# GD32A72_A74x register map
File version: 1.0
CPU: CM7 r2p1, little endian, MPU, FPU, DSP, 4 interrupt priority bits
Registers are 32-bit, read-write, reset 0x0 unless marked. A register's access mark holds for its fields unless they carry their own. Offsets are from the block's base; [hi:lo] are bit positions; {n}, {i} and the like mark numbered series; 'fields as' and 'values as' point back to an identical list.

## TCM
Base 0x49004000
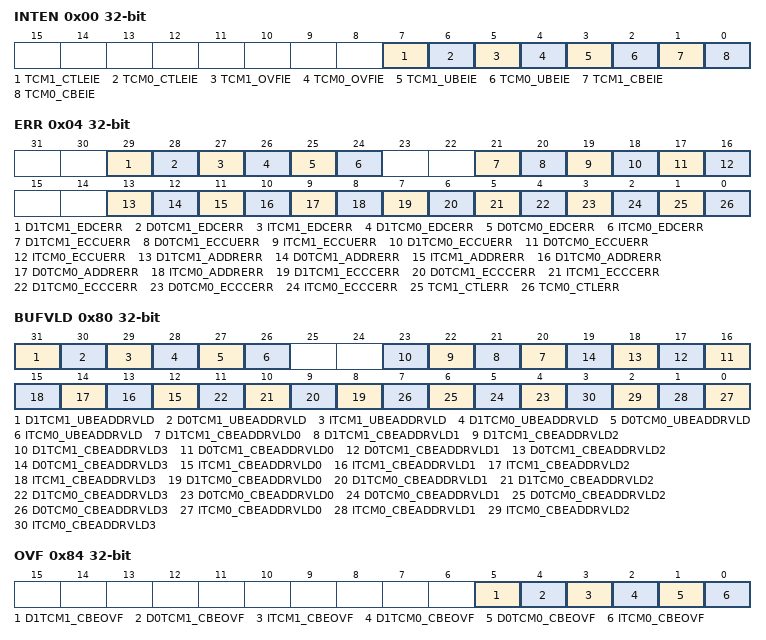
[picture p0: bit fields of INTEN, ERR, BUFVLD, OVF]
0x00 INTEN — TCM interrupt enable register
  [7] TCM1_CTLEIE — TCM of CM7_1 controller redundancy check error interrupt enable
  [6] TCM0_CTLEIE — TCM of CM7_0 controller redundancy check error interrupt enable
  [5] TCM1_OVFIE — TCM of M7_1 address buffer overflow interrupt enable
  [4] TCM0_OVFIE — TCM of M7_0 address buffer overflow interrupt enable
  [3] TCM1_UBEIE — TCM of M7_1 uncorrectable bit error interrupt enable
  [2] TCM0_UBEIE — TCM of M7_0 uncorrectable bit error interrupt enable
  [1] TCM1_CBEIE — TCM of M7_1 correctable bit error interrupt enable
  [0] TCM0_CBEIE — TCM of M7_0 correctable bit error interrupt enable
0x04 ERR — TCM error status register
  [29] D1TCM1_EDCERR — D1TCM of M7_1 EDC after ECC checker error flag
  [28] D0TCM1_EDCERR — D0TCM of M7_1 EDC after ECC checker error flag
  [27] ITCM1_EDCERR — ITCM of M7_1 EDC after ECC checker error flag
  [26] D1TCM0_EDCERR — D1TCM of M7_0 EDC after ECC checker error flag
  [25] D0TCM0_EDCERR — D0TCM of M7_0 EDC after ECC checker error flag
  [24] ITCM0_EDCERR — ITCM of M7_0 EDC after ECC checker error flag
  [21] D1TCM1_ECCUERR — D1TCM of M7_1 ECC double bit uncorrectable error flag
  [20] D0TCM1_ECCUERR — D0TCM of M7_1 ECC double bit uncorrectable error flag
  [19] ITCM1_ECCUERR — ITCM of M7_1 ECC double bit uncorrectable error flag
  [18] D1TCM0_ECCUERR — D1TCM of M7_0 ECC double bit uncorrectable error flag
  [17] D0TCM0_ECCUERR — D0TCM of M7_0 ECC double bit uncorrectable error flag
  [16] ITCM0_ECCUERR — ITCM of M7_0 ECC double bit uncorrectable error flag
  [13] D1TCM1_ADDRERR — D1TCM of M7_1 single bit address error flag
  [12] D0TCM1_ADDRERR — D0TCM of M7_1 single bit address error flag
  [11] ITCM1_ADDRERR — ITCM of M7_1 single bit address error flag
  [10] D1TCM0_ADDRERR — D1TCM of M7_0 single bit address error flag
  [9] D0TCM0_ADDRERR — D0TCM of M7_0 single bit address error flag
  [8] ITCM0_ADDRERR — ITCM of M7_0 single bit address error flag
  [7] D1TCM1_ECCCERR — D1TCM of M7_1 single bit correctable error flag
  [6] D0TCM1_ECCCERR — D0TCM of M7_1 single bit correctable error flag
  [5] ITCM1_ECCCERR — ITCM of M7_1 single bit correctable error flag
  [4] D1TCM0_ECCCERR — D1TCM of M7_0 single bit correctable error flag
  [3] D0TCM0_ECCCERR — D0TCM of M7_0 single bit correctable error flag
  [2] ITCM0_ECCCERR — ITCM of M7_0 single bit correctable error flag
  [1] TCM1_CTLERR — TCM of M7_1 controller redundancy check error flag
  [0] TCM0_CTLERR — TCM of M7_0 controller redundancy check error flag
0x08 CBEADDR0_0 ro — TCM correctable bit error address 0 for SRAM_0 register
  [31:0] TCM_CBEADDR0 — Record the first correctable bit error address
0x0C CBEADDR0_1 ro — TCM correctable bit error address 0 for SRAM_1 register
  [31:0] TCM_CBEADDR0 — Record the first correctable bit error address
0x10 CBEADDR0_2 ro reset 0x4 — TCM correctable bit error address 0 for SRAM_2 register
  [31:0] TCM_CBEADDR0 — Record the first correctable bit error address
0x14 CBEADDR0_3 ro — TCM correctable bit error address 0 for SRAM_3 register
  [31:0] TCM_CBEADDR0 — Record the first correctable bit error address
0x18 CBEADDR0_4 ro — TCM correctable bit error address 0 for SRAM_4 register
  [31:0] TCM_CBEADDR0 — Record the first correctable bit error address
0x1C CBEADDR0_5 ro reset 0x4 — TCM correctable bit error address 0 for SRAM_5 register
  [31:0] TCM_CBEADDR0 — Record the first correctable bit error address
0x20 CBEADDR1_0 ro — TCM correctable bit error address 1 for SRAM_0 register
  [31:0] TCM_CBEADDR1 — Record the second correctable bit error address
0x24 CBEADDR1_1 ro — TCM correctable bit error address 1 for SRAM_1 register
  fields as CBEADDR1_0
0x28 CBEADDR1_2 ro reset 0x4 — TCM correctable bit error address 1 for SRAM_2 register
  fields as CBEADDR1_0
0x2C CBEADDR1_3 ro — TCM correctable bit error address 1 for SRAM_3 register
  fields as CBEADDR1_0
0x30 CBEADDR1_4 ro — TCM correctable bit error address 1 for SRAM_4 register
  fields as CBEADDR1_0
0x34 CBEADDR1_5 ro reset 0x4 — TCM correctable bit error address 1 for SRAM_5 register
  fields as CBEADDR1_0
0x38 CBEADDR2_0 ro — TCM correctable bit error address 2 for SRAM_0 register
  [31:0] TCM_CBEADDR2 — Record the third correctable bit error address
0x3C CBEADDR2_1 ro — TCM correctable bit error address 2 for SRAM_1 register
  [31:0] TCM_CBEADDR2 — Record the third correctable bit error address
0x40 CBEADDR2_2 ro reset 0x4 — TCM correctable bit error address 2 for SRAM_2 register
  [31:0] TCM_CBEADDR2 — Record the third correctable bit error address
0x44 CBEADDR2_3 ro — TCM correctable bit error address 2 for SRAM_3 register
  [31:0] TCM_CBEADDR2 — Record the third correctable bit error address
0x48 CBEADDR2_4 ro — TCM correctable bit error address 2 for SRAM_4 register
  [31:0] TCM_CBEADDR2 — Record the third correctable bit error address
0x4C CBEADDR2_5 ro reset 0x4 — TCM correctable bit error address 2 for SRAM_5 register
  [31:0] TCM_CBEADDR2 — Record the third correctable bit error address
0x50 CBEADDR3_0 ro — TCM correctable bit error address 3 for SRAM_0 register
  [31:0] TCM_CBEADDR3 — Record the fourth correctable bit error address
0x54 CBEADDR3_1 ro — TCM correctable bit error address 3 for SRAM_1 register
  fields as CBEADDR3_0
0x58 CBEADDR3_2 ro reset 0x4 — TCM correctable bit error address 3 for SRAM_2 register
  fields as CBEADDR3_0
{0x50+4i} CBEADDR3_{i} ro (i=3..5) — TCM correctable bit error address 3 for SRAM_{i} register
  fields as CBEADDR3_0
0x68 UBEADDR_0 ro — TCM uncorrectable bit error address for SRAM_0 register
  [31:0] TCM_UBEADDR — record the un-correctable bit error address
0x6C UBEADDR_1 ro — TCM uncorrectable bit error address for SRAM_1 register
  [31:0] TCM_UBEADDR — record the un-correctable bit error address
0x70 UBEADDR_2 ro reset 0x4 — TCM uncorrectable bit error address for SRAM_2 register
  [31:0] TCM_UBEADDR — Record the correctable bit error address
0x74 UBEADDR_3 ro — TCM uncorrectable bit error address for SRAM_3 register
  [31:0] TCM_UBEADDR — Record the correctable bit error address
0x78 UBEADDR_4 ro — TCM uncorrectable bit error address for SRAM_4 register
  [31:0] TCM_UBEADDR — Record the correctable bit error address
0x7C UBEADDR_5 ro reset 0x4 — TCM uncorrectable bit error address for SRAM_5 register
  [31:0] TCM_UBEADDR — record the un-correctable bit error address
0x80 BUFVLD — TCM buffer valid register
  [31] D1TCM1_UBEADDRVLD — D1TCM of M7_1 un-correctable bit error address valid flag
  [30] D0TCM1_UBEADDRVLD — D0TCM of M7_1 un-correctable bit error address valid flag
  [29] ITCM1_UBEADDRVLD — ITCM of M7_1 un-correctable bit error address valid flag
  [28] D1TCM0_UBEADDRVLD — D1TCM of M7_0 un-correctable bit error address valid flag
  [27] D0TCM0_UBEADDRVLD — D0TCM of M7_0 un-correctable bit error address valid flag
  [26] ITCM0_UBEADDRVLD — ITCM of M7_0 un-correctable bit error address valid flag
  [n+20] D1TCM1_CBEADDRVLD{n} (n=0..3) — D1TCM of M7_1 correctable bit error address{n} valid flag
  [n+16] D0TCM1_CBEADDRVLD{n} (n=0..3) — D0TCM of M7_1 correctable bit error address{n} valid flag
  [n+12] ITCM1_CBEADDRVLD{n} (n=0..3) — ITCM of M7_1 correctable bit error address{n} valid flag
  [n+8] D1TCM0_CBEADDRVLD{n} (n=0..3) — D1TCM of M7_0 correctable bit error address{n} valid flag
  [n+4] D0TCM0_CBEADDRVLD{n} (n=0..3) — D0TCM of M7_0 correctable bit error address{n} valid flag
  [n] ITCM0_CBEADDRVLD{n} (n=0..3) — ITCM of M7_0 correctable bit error address{n} valid flag
0x84 OVF — SRAM overflow status register
  [5] D1TCM1_CBEOVF — D1TCM of M7_1 correctable bit error address buffer overflow
  [4] D0TCM1_CBEOVF — D0TCM of M7_1 correctable bit error address buffer overflow
  [3] ITCM1_CBEOVF — ITCM of M7_1 correctable bit error address buffer overflow
  [2] D1TCM0_CBEOVF — D1TCM of M7_0 correctable bit error address buffer overflow
  [1] D0TCM0_CBEOVF — D0TCM of M7_0 correctable bit error address buffer overflow
  [0] ITCM0_CBEOVF — ITCM of M7_0 correctable bit error address buffer overflow
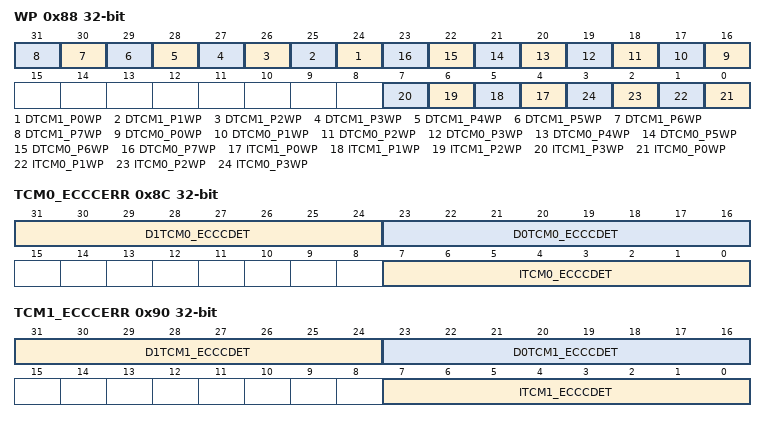
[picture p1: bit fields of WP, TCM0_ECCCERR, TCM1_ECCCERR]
0x88 WP — TCM write protection register
  [n+24] DTCM1_P{n}WP (n=0..7) — DTCM1 of CM7 page {n} write protection (a page granularity is 8 Kbyte)
  [n+16] DTCM0_P{n}WP (n=0..7) — DTCM0 of CM7 page {n} write protection (a page granularity is 8 Kbyte)
  [n+4] ITCM1_P{n}WP (n=0..3) — ITCM1 of CM7 page {n} write protection (a page granularity is 8 Kbyte)
  [n] ITCM0_P{n}WP (n=0..3) — ITCM0 of CM7 page {n} write protection (a page granularity is 8 Kbyte)
0x8C TCM0_ECCCERR — TCM0 ECC code error status register
  [31:24] D1TCM0_ECCCDET — D0TCM of M7_0 ecc code calculated with check error detected to identify the position on a single-bit inversion
  [23:16] D0TCM0_ECCCDET — D0TCM of M7_0 ecc code calculated with check error detected to identify the position on a single-bit inversion
  [7:0] ITCM0_ECCCDET — ITCM of M7_0 ecc code calculated with check error detected to identify the position on a single-bit inversion
0x90 TCM1_ECCCERR — TCM1 ECC code error status register
  [31:24] D1TCM1_ECCCDET — D0TCM of M7_1 ecc code calculated with check error detected to identify the position on a single-bit inversion
  [23:16] D0TCM1_ECCCDET — D0TCM of M7_1 ecc code calculated with check error detected to identify the position on a single-bit inversion
  [7:0] ITCM1_ECCCDET — ITCM of M7_1 ecc code calculated with check error detected to identify the position on a single-bit inversion
